AUTOSAR XML (schema 4-0-3)
standard types defined: Boolean, UInt16, UInt8
package /AUTOSAR_Platform/DataConstrs
  range DC_Boolean: raw 0..1
  range DC_UInt16: raw 0..65535
  range DC_UInt8: raw 0..255
package /PATAC/MSM/ComponentTypes
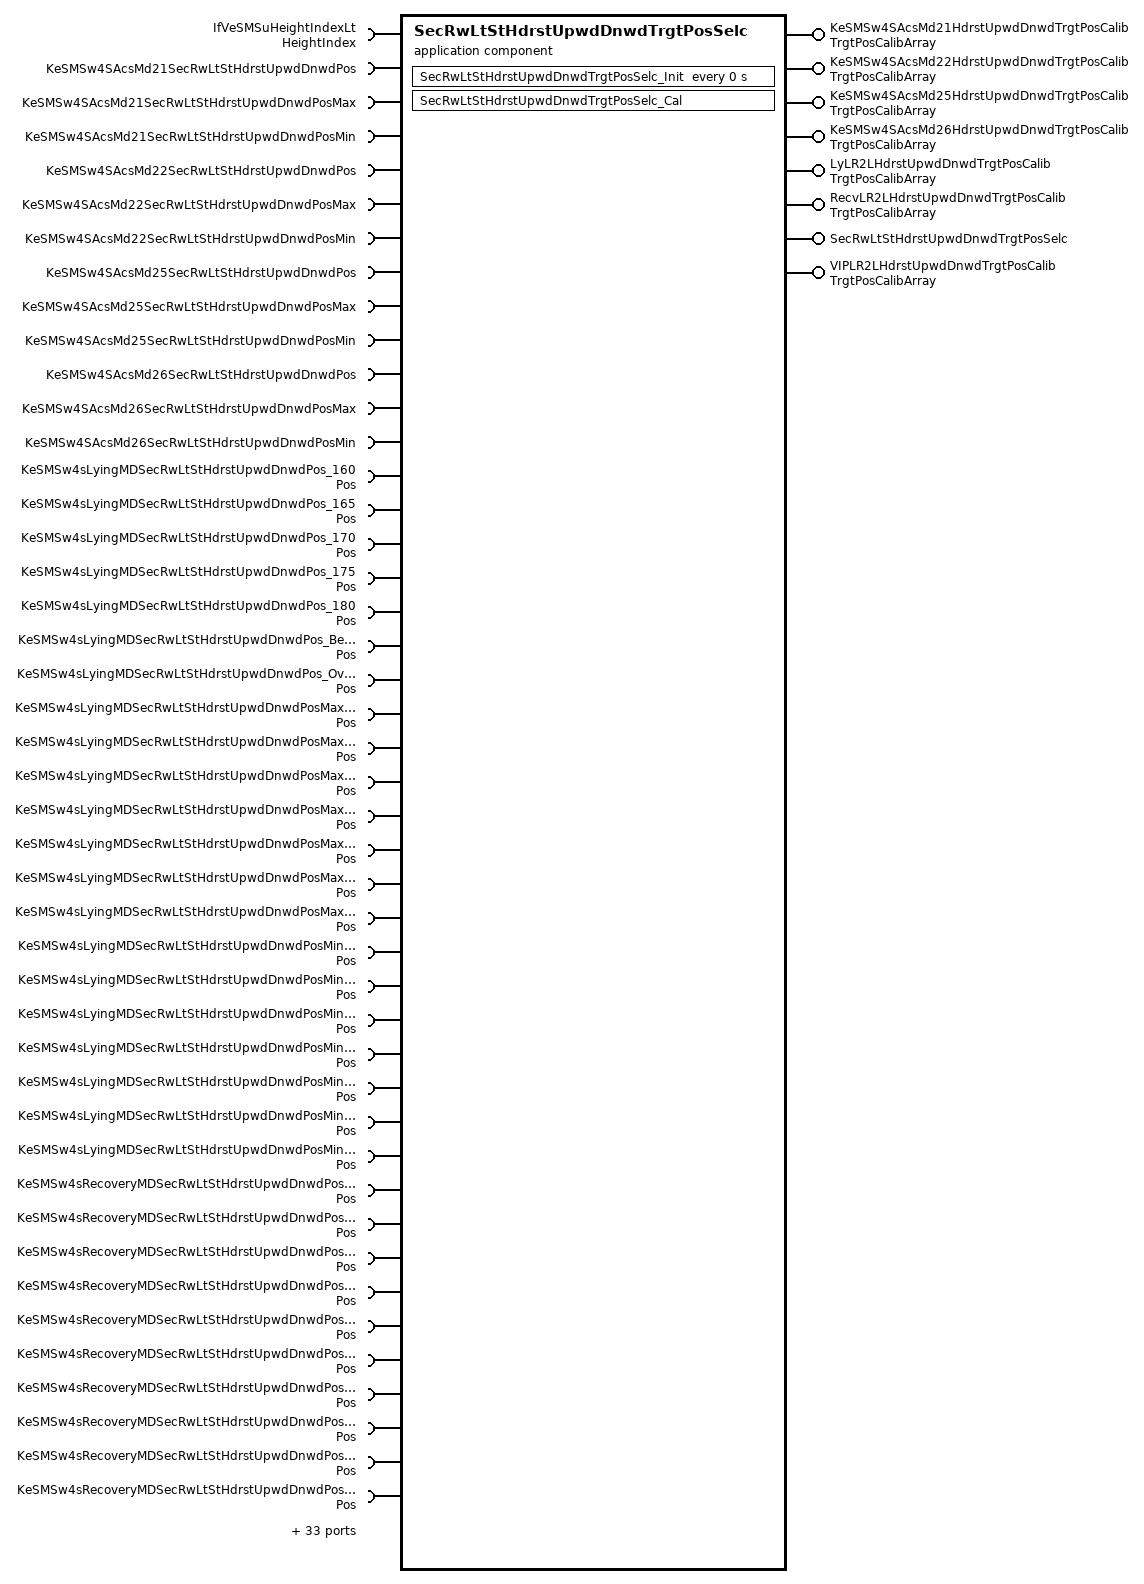
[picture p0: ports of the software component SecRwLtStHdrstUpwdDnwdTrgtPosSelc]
  application sw component type SecRwLtStHdrstUpwdDnwdTrgtPosSelc
    8 x provide port:
      KeSMSw4SAcsMd21HdrstUpwdDnwdTrgtPosCalib: nonqueued-sender-com-spec{data-element=TrgtPosArray, init-value=[4095, 4095, 4095]}, provided-interface=TrgtPosCalibArray
      KeSMSw4SAcsMd22HdrstUpwdDnwdTrgtPosCalib: nonqueued-sender-com-spec{data-element=TrgtPosArray, init-value=[4095, 4095, 4095]}, provided-interface=TrgtPosCalibArray
      KeSMSw4SAcsMd25HdrstUpwdDnwdTrgtPosCalib: nonqueued-sender-com-spec{data-element=TrgtPosArray, init-value=[4095, 4095, 4095]}, provided-interface=TrgtPosCalibArray
      KeSMSw4SAcsMd26HdrstUpwdDnwdTrgtPosCalib: nonqueued-sender-com-spec{data-element=TrgtPosArray, init-value=[4095, 4095, 4095]}, provided-interface=TrgtPosCalibArray
      LyLR2LHdrstUpwdDnwdTrgtPosCalib: nonqueued-sender-com-spec{data-element=TrgtPosArray, init-value=[4095, 4095, 4095]}, provided-interface=TrgtPosCalibArray
      RecvLR2LHdrstUpwdDnwdTrgtPosCalib: nonqueued-sender-com-spec{data-element=TrgtPosArray, init-value=[4095, 4095, 4095]}, provided-interface=TrgtPosCalibArray
      SecRwLtStHdrstUpwdDnwdTrgtPosSelc: server-com-spec{operation=Cal, queue-length=1}, provided-interface=SecRwLtStHdrstUpwdDnwdTrgtPosSelc
      VIPLR2LHdrstUpwdDnwdTrgtPosCalib: nonqueued-sender-com-spec{data-element=TrgtPosArray, init-value=[4095, 4095, 4095]}, provided-interface=TrgtPosCalibArray
    77 x require port:
      IfVeSMSuHeightIndexLt: nonqueued-receiver-com-spec{data-element=Val, filter=data-filter-type=ALWAYS, init-value=0}, required-interface=HeightIndex
      KeSMSw4SAcsMd21SecRwLtStHdrstUpwdDnwdPos: parameter-require-com-spec{init-value=0, parameter=KeSMSw4SAcsMd21SecRwLtStHdrstUpwdDnwdPos/Val}, required-interface=KeSMSw4SAcsMd21SecRwLtStHdrstUpwdDnwdPos
      KeSMSw4SAcsMd21SecRwLtStHdrstUpwdDnwdPosMax: parameter-require-com-spec{init-value=0, parameter=KeSMSw4SAcsMd21SecRwLtStHdrstUpwdDnwdPosMax/Val}, required-interface=KeSMSw4SAcsMd21SecRwLtStHdrstUpwdDnwdPosMax
      KeSMSw4SAcsMd21SecRwLtStHdrstUpwdDnwdPosMin: parameter-require-com-spec{init-value=0, parameter=KeSMSw4SAcsMd21SecRwLtStHdrstUpwdDnwdPosMin/Val}, required-interface=KeSMSw4SAcsMd21SecRwLtStHdrstUpwdDnwdPosMin
      KeSMSw4SAcsMd22SecRwLtStHdrstUpwdDnwdPos: parameter-require-com-spec{init-value=0, parameter=KeSMSw4SAcsMd22SecRwLtStHdrstUpwdDnwdPos/Val}, required-interface=KeSMSw4SAcsMd22SecRwLtStHdrstUpwdDnwdPos
      KeSMSw4SAcsMd22SecRwLtStHdrstUpwdDnwdPosMax: parameter-require-com-spec{init-value=0, parameter=KeSMSw4SAcsMd22SecRwLtStHdrstUpwdDnwdPosMax/Val}, required-interface=KeSMSw4SAcsMd22SecRwLtStHdrstUpwdDnwdPosMax
      KeSMSw4SAcsMd22SecRwLtStHdrstUpwdDnwdPosMin: parameter-require-com-spec{init-value=0, parameter=KeSMSw4SAcsMd22SecRwLtStHdrstUpwdDnwdPosMin/Val}, required-interface=KeSMSw4SAcsMd22SecRwLtStHdrstUpwdDnwdPosMin
      KeSMSw4SAcsMd25SecRwLtStHdrstUpwdDnwdPos: parameter-require-com-spec{init-value=0, parameter=KeSMSw4SAcsMd25SecRwLtStHdrstUpwdDnwdPos/Val}, required-interface=KeSMSw4SAcsMd25SecRwLtStHdrstUpwdDnwdPos
      KeSMSw4SAcsMd25SecRwLtStHdrstUpwdDnwdPosMax: parameter-require-com-spec{init-value=0, parameter=KeSMSw4SAcsMd25SecRwLtStHdrstUpwdDnwdPosMax/Val}, required-interface=KeSMSw4SAcsMd25SecRwLtStHdrstUpwdDnwdPosMax
      KeSMSw4SAcsMd25SecRwLtStHdrstUpwdDnwdPosMin: parameter-require-com-spec{init-value=0, parameter=KeSMSw4SAcsMd25SecRwLtStHdrstUpwdDnwdPosMin/Val}, required-interface=KeSMSw4SAcsMd25SecRwLtStHdrstUpwdDnwdPosMin
      KeSMSw4SAcsMd26SecRwLtStHdrstUpwdDnwdPos: parameter-require-com-spec{init-value=0, parameter=KeSMSw4SAcsMd26SecRwLtStHdrstUpwdDnwdPos/Val}, required-interface=KeSMSw4SAcsMd26SecRwLtStHdrstUpwdDnwdPos
      KeSMSw4SAcsMd26SecRwLtStHdrstUpwdDnwdPosMax: parameter-require-com-spec{init-value=0, parameter=KeSMSw4SAcsMd26SecRwLtStHdrstUpwdDnwdPosMax/Val}, required-interface=KeSMSw4SAcsMd26SecRwLtStHdrstUpwdDnwdPosMax
      KeSMSw4SAcsMd26SecRwLtStHdrstUpwdDnwdPosMin: parameter-require-com-spec{init-value=0, parameter=KeSMSw4SAcsMd26SecRwLtStHdrstUpwdDnwdPosMin/Val}, required-interface=KeSMSw4SAcsMd26SecRwLtStHdrstUpwdDnwdPosMin
      KeSMSw4sLyingMDSecRwLtStHdrstUpwdDnwdPos_160: parameter-require-com-spec{init-value=0, parameter=Pos/Val}, required-interface=Pos
      KeSMSw4sLyingMDSecRwLtStHdrstUpwdDnwdPos_165: parameter-require-com-spec{init-value=0, parameter=Pos/Val}, required-interface=Pos
      KeSMSw4sLyingMDSecRwLtStHdrstUpwdDnwdPos_170: parameter-require-com-spec{init-value=0, parameter=Pos/Val}, required-interface=Pos
      KeSMSw4sLyingMDSecRwLtStHdrstUpwdDnwdPos_175: parameter-require-com-spec{init-value=0, parameter=Pos/Val}, required-interface=Pos
      KeSMSw4sLyingMDSecRwLtStHdrstUpwdDnwdPos_180: parameter-require-com-spec{init-value=0, parameter=Pos/Val}, required-interface=Pos
      KeSMSw4sLyingMDSecRwLtStHdrstUpwdDnwdPos_Below160: parameter-require-com-spec{init-value=0, parameter=Pos/Val}, required-interface=Pos
      KeSMSw4sLyingMDSecRwLtStHdrstUpwdDnwdPos_Over180: parameter-require-com-spec{init-value=0, parameter=Pos/Val}, required-interface=Pos
      KeSMSw4sLyingMDSecRwLtStHdrstUpwdDnwdPosMax_160: parameter-require-com-spec{init-value=0, parameter=Pos/Val}, required-interface=Pos
      KeSMSw4sLyingMDSecRwLtStHdrstUpwdDnwdPosMax_165: parameter-require-com-spec{init-value=0, parameter=Pos/Val}, required-interface=Pos
      KeSMSw4sLyingMDSecRwLtStHdrstUpwdDnwdPosMax_170: parameter-require-com-spec{init-value=0, parameter=Pos/Val}, required-interface=Pos
      KeSMSw4sLyingMDSecRwLtStHdrstUpwdDnwdPosMax_175: parameter-require-com-spec{init-value=0, parameter=Pos/Val}, required-interface=Pos
      KeSMSw4sLyingMDSecRwLtStHdrstUpwdDnwdPosMax_180: parameter-require-com-spec{init-value=0, parameter=Pos/Val}, required-interface=Pos
      KeSMSw4sLyingMDSecRwLtStHdrstUpwdDnwdPosMax_Below160: parameter-require-com-spec{init-value=0, parameter=Pos/Val}, required-interface=Pos
      KeSMSw4sLyingMDSecRwLtStHdrstUpwdDnwdPosMax_Over180: parameter-require-com-spec{init-value=0, parameter=Pos/Val}, required-interface=Pos
      KeSMSw4sLyingMDSecRwLtStHdrstUpwdDnwdPosMin_160: parameter-require-com-spec{init-value=0, parameter=Pos/Val}, required-interface=Pos
      KeSMSw4sLyingMDSecRwLtStHdrstUpwdDnwdPosMin_165: parameter-require-com-spec{init-value=0, parameter=Pos/Val}, required-interface=Pos
      KeSMSw4sLyingMDSecRwLtStHdrstUpwdDnwdPosMin_170: parameter-require-com-spec{init-value=0, parameter=Pos/Val}, required-interface=Pos
      KeSMSw4sLyingMDSecRwLtStHdrstUpwdDnwdPosMin_175: parameter-require-com-spec{init-value=0, parameter=Pos/Val}, required-interface=Pos
      KeSMSw4sLyingMDSecRwLtStHdrstUpwdDnwdPosMin_180: parameter-require-com-spec{init-value=0, parameter=Pos/Val}, required-interface=Pos
      KeSMSw4sLyingMDSecRwLtStHdrstUpwdDnwdPosMin_Below160: parameter-require-com-spec{init-value=0, parameter=Pos/Val}, required-interface=Pos
      KeSMSw4sLyingMDSecRwLtStHdrstUpwdDnwdPosMin_Over180: parameter-require-com-spec{init-value=0, parameter=Pos/Val}, required-interface=Pos
      KeSMSw4sRecoveryMDSecRwLtStHdrstUpwdDnwdPos_160: parameter-require-com-spec{init-value=0, parameter=Pos/Val}, required-interface=Pos
      KeSMSw4sRecoveryMDSecRwLtStHdrstUpwdDnwdPos_165: parameter-require-com-spec{init-value=0, parameter=Pos/Val}, required-interface=Pos
      KeSMSw4sRecoveryMDSecRwLtStHdrstUpwdDnwdPos_170: parameter-require-com-spec{init-value=0, parameter=Pos/Val}, required-interface=Pos
      KeSMSw4sRecoveryMDSecRwLtStHdrstUpwdDnwdPos_175: parameter-require-com-spec{init-value=0, parameter=Pos/Val}, required-interface=Pos
      KeSMSw4sRecoveryMDSecRwLtStHdrstUpwdDnwdPos_180: parameter-require-com-spec{init-value=0, parameter=Pos/Val}, required-interface=Pos
      KeSMSw4sRecoveryMDSecRwLtStHdrstUpwdDnwdPos_Below160: parameter-require-com-spec{init-value=0, parameter=Pos/Val}, required-interface=Pos
      KeSMSw4sRecoveryMDSecRwLtStHdrstUpwdDnwdPos_Over180: parameter-require-com-spec{init-value=0, parameter=Pos/Val}, required-interface=Pos
      KeSMSw4sRecoveryMDSecRwLtStHdrstUpwdDnwdPosMax_160: parameter-require-com-spec{init-value=0, parameter=Pos/Val}, required-interface=Pos
      KeSMSw4sRecoveryMDSecRwLtStHdrstUpwdDnwdPosMax_165: parameter-require-com-spec{init-value=0, parameter=Pos/Val}, required-interface=Pos
      KeSMSw4sRecoveryMDSecRwLtStHdrstUpwdDnwdPosMax_170: parameter-require-com-spec{init-value=0, parameter=Pos/Val}, required-interface=Pos
      KeSMSw4sRecoveryMDSecRwLtStHdrstUpwdDnwdPosMax_175: parameter-require-com-spec{init-value=0, parameter=Pos/Val}, required-interface=Pos
      KeSMSw4sRecoveryMDSecRwLtStHdrstUpwdDnwdPosMax_180: parameter-require-com-spec{init-value=0, parameter=Pos/Val}, required-interface=Pos
      KeSMSw4sRecoveryMDSecRwLtStHdrstUpwdDnwdPosMax_Below160: parameter-require-com-spec{init-value=0, parameter=Pos/Val}, required-interface=Pos
      KeSMSw4sRecoveryMDSecRwLtStHdrstUpwdDnwdPosMax_Over180: parameter-require-com-spec{init-value=0, parameter=Pos/Val}, required-interface=Pos
      KeSMSw4sRecoveryMDSecRwLtStHdrstUpwdDnwdPosMin_160: parameter-require-com-spec{init-value=0, parameter=Pos/Val}, required-interface=Pos
      KeSMSw4sRecoveryMDSecRwLtStHdrstUpwdDnwdPosMin_165: parameter-require-com-spec{init-value=0, parameter=Pos/Val}, required-interface=Pos
      KeSMSw4sRecoveryMDSecRwLtStHdrstUpwdDnwdPosMin_170: parameter-require-com-spec{init-value=0, parameter=Pos/Val}, required-interface=Pos
      KeSMSw4sRecoveryMDSecRwLtStHdrstUpwdDnwdPosMin_175: parameter-require-com-spec{init-value=0, parameter=Pos/Val}, required-interface=Pos
      KeSMSw4sRecoveryMDSecRwLtStHdrstUpwdDnwdPosMin_180: parameter-require-com-spec{init-value=0, parameter=Pos/Val}, required-interface=Pos
      KeSMSw4sRecoveryMDSecRwLtStHdrstUpwdDnwdPosMin_Below160: parameter-require-com-spec{init-value=0, parameter=Pos/Val}, required-interface=Pos
      KeSMSw4sRecoveryMDSecRwLtStHdrstUpwdDnwdPosMin_Over180: parameter-require-com-spec{init-value=0, parameter=Pos/Val}, required-interface=Pos
      KeSMSw4sVIPMDSecRwLtStHdrstUpwdDnwdPos_160: parameter-require-com-spec{init-value=0, parameter=Pos/Val}, required-interface=Pos
      KeSMSw4sVIPMDSecRwLtStHdrstUpwdDnwdPos_165: parameter-require-com-spec{init-value=0, parameter=Pos/Val}, required-interface=Pos
      KeSMSw4sVIPMDSecRwLtStHdrstUpwdDnwdPos_170: parameter-require-com-spec{init-value=0, parameter=Pos/Val}, required-interface=Pos
      KeSMSw4sVIPMDSecRwLtStHdrstUpwdDnwdPos_175: parameter-require-com-spec{init-value=0, parameter=Pos/Val}, required-interface=Pos
      KeSMSw4sVIPMDSecRwLtStHdrstUpwdDnwdPos_180: parameter-require-com-spec{init-value=0, parameter=Pos/Val}, required-interface=Pos
      KeSMSw4sVIPMDSecRwLtStHdrstUpwdDnwdPos_Below160: parameter-require-com-spec{init-value=0, parameter=Pos/Val}, required-interface=Pos
      KeSMSw4sVIPMDSecRwLtStHdrstUpwdDnwdPos_Over180: parameter-require-com-spec{init-value=0, parameter=Pos/Val}, required-interface=Pos
      KeSMSw4sVIPMDSecRwLtStHdrstUpwdDnwdPosMax_160: parameter-require-com-spec{init-value=0, parameter=Pos/Val}, required-interface=Pos
      KeSMSw4sVIPMDSecRwLtStHdrstUpwdDnwdPosMax_165: parameter-require-com-spec{init-value=0, parameter=Pos/Val}, required-interface=Pos
      KeSMSw4sVIPMDSecRwLtStHdrstUpwdDnwdPosMax_170: parameter-require-com-spec{init-value=0, parameter=Pos/Val}, required-interface=Pos
      KeSMSw4sVIPMDSecRwLtStHdrstUpwdDnwdPosMax_175: parameter-require-com-spec{init-value=0, parameter=Pos/Val}, required-interface=Pos
      KeSMSw4sVIPMDSecRwLtStHdrstUpwdDnwdPosMax_180: parameter-require-com-spec{init-value=0, parameter=Pos/Val}, required-interface=Pos
      KeSMSw4sVIPMDSecRwLtStHdrstUpwdDnwdPosMax_Below160: parameter-require-com-spec{init-value=0, parameter=Pos/Val}, required-interface=Pos
      KeSMSw4sVIPMDSecRwLtStHdrstUpwdDnwdPosMax_Over180: parameter-require-com-spec{init-value=0, parameter=Pos/Val}, required-interface=Pos
      KeSMSw4sVIPMDSecRwLtStHdrstUpwdDnwdPosMin_160: parameter-require-com-spec{init-value=0, parameter=Pos/Val}, required-interface=Pos
      KeSMSw4sVIPMDSecRwLtStHdrstUpwdDnwdPosMin_165: parameter-require-com-spec{init-value=0, parameter=Pos/Val}, required-interface=Pos
      KeSMSw4sVIPMDSecRwLtStHdrstUpwdDnwdPosMin_170: parameter-require-com-spec{init-value=0, parameter=Pos/Val}, required-interface=Pos
      KeSMSw4sVIPMDSecRwLtStHdrstUpwdDnwdPosMin_175: parameter-require-com-spec{init-value=0, parameter=Pos/Val}, required-interface=Pos
      KeSMSw4sVIPMDSecRwLtStHdrstUpwdDnwdPosMin_180: parameter-require-com-spec{init-value=0, parameter=Pos/Val}, required-interface=Pos
      KeSMSw4sVIPMDSecRwLtStHdrstUpwdDnwdPosMin_Below160: parameter-require-com-spec{init-value=0, parameter=Pos/Val}, required-interface=Pos
      KeSMSw4sVIPMDSecRwLtStHdrstUpwdDnwdPosMin_Over180: parameter-require-com-spec{init-value=0, parameter=Pos/Val}, required-interface=Pos
      StNumFlg: required-interface=StNumFlg
        required-com-specs:
          data-element=Is4s, filter=data-filter-type=ALWAYS, init-value=0
          data-element=Is6s, filter=data-filter-type=ALWAYS, init-value=0
          data-element=Is6s7s, filter=data-filter-type=ALWAYS, init-value=0
          data-element=Is7s, filter=data-filter-type=ALWAYS, init-value=0
    behavior SecRwLtStHdrstUpwdDnwdTrgtPosSelc_InternalBehavior
      operation invoked event OIT_SecRwLtStHdrstUpwdDnwdTrgtPosSelc_Cal_SecRwLtStHdrstUpwdDnwdTrgtPosSelc_Cal: start-on-event=SecRwLtStHdrstUpwdDnwdTrgtPosSelc_Cal, operation=SecRwLtStHdrstUpwdDnwdTrgtPosSelc.Cal
      timing event SecRwLtStHdrstUpwdDnwdTrgtPosSelc_InitEvent: start-on-event=SecRwLtStHdrstUpwdDnwdTrgtPosSelc_Init, period=0
      runnable SecRwLtStHdrstUpwdDnwdTrgtPosSelc_Cal
        data-receive-point-by-arguments:
          5 x access:
            REC_IfVeSMSuHeightIndexLt_Val: accessed-variable=IfVeSMSuHeightIndexLt.Val
            REC_StNumFlg_Is4s: accessed-variable=StNumFlg.Is4s
            REC_StNumFlg_Is6s: accessed-variable=StNumFlg.Is6s
            REC_StNumFlg_Is6s7s: accessed-variable=StNumFlg.Is6s7s
            REC_StNumFlg_Is7s: accessed-variable=StNumFlg.Is7s
        data-send-points:
          7 x access:
            SEND_KeSMSw4SAcsMd21HdrstUpwdDnwdTrgtPosCalib_TrgtPosArray: accessed-variable=KeSMSw4SAcsMd21HdrstUpwdDnwdTrgtPosCalib.TrgtPosArray
            SEND_KeSMSw4SAcsMd22HdrstUpwdDnwdTrgtPosCalib_TrgtPosArray: accessed-variable=KeSMSw4SAcsMd22HdrstUpwdDnwdTrgtPosCalib.TrgtPosArray
            SEND_KeSMSw4SAcsMd25HdrstUpwdDnwdTrgtPosCalib_TrgtPosArray: accessed-variable=KeSMSw4SAcsMd25HdrstUpwdDnwdTrgtPosCalib.TrgtPosArray
            SEND_KeSMSw4SAcsMd26HdrstUpwdDnwdTrgtPosCalib_TrgtPosArray: accessed-variable=KeSMSw4SAcsMd26HdrstUpwdDnwdTrgtPosCalib.TrgtPosArray
            SEND_LyLR2LHdrstUpwdDnwdTrgtPosCalib_TrgtPosArray: accessed-variable=LyLR2LHdrstUpwdDnwdTrgtPosCalib.TrgtPosArray
            SEND_RecvLR2LHdrstUpwdDnwdTrgtPosCalib_TrgtPosArray: accessed-variable=RecvLR2LHdrstUpwdDnwdTrgtPosCalib.TrgtPosArray
            SEND_VIPLR2LHdrstUpwdDnwdTrgtPosCalib_TrgtPosArray: accessed-variable=VIPLR2LHdrstUpwdDnwdTrgtPosCalib.TrgtPosArray
        75 x parameter access:
          PA_KeSMSw4SAcsMd21SecRwLtStHdrstUpwdDnwdPos_Val: accessed-parameter=KeSMSw4SAcsMd21SecRwLtStHdrstUpwdDnwdPos.Val
          PA_KeSMSw4SAcsMd21SecRwLtStHdrstUpwdDnwdPosMax_Val: accessed-parameter=KeSMSw4SAcsMd21SecRwLtStHdrstUpwdDnwdPosMax.Val
          PA_KeSMSw4SAcsMd21SecRwLtStHdrstUpwdDnwdPosMin_Val: accessed-parameter=KeSMSw4SAcsMd21SecRwLtStHdrstUpwdDnwdPosMin.Val
          PA_KeSMSw4SAcsMd22SecRwLtStHdrstUpwdDnwdPos_Val: accessed-parameter=KeSMSw4SAcsMd22SecRwLtStHdrstUpwdDnwdPos.Val
          PA_KeSMSw4SAcsMd22SecRwLtStHdrstUpwdDnwdPosMax_Val: accessed-parameter=KeSMSw4SAcsMd22SecRwLtStHdrstUpwdDnwdPosMax.Val
          PA_KeSMSw4SAcsMd22SecRwLtStHdrstUpwdDnwdPosMin_Val: accessed-parameter=KeSMSw4SAcsMd22SecRwLtStHdrstUpwdDnwdPosMin.Val
          PA_KeSMSw4SAcsMd25SecRwLtStHdrstUpwdDnwdPos_Val: accessed-parameter=KeSMSw4SAcsMd25SecRwLtStHdrstUpwdDnwdPos.Val
          PA_KeSMSw4SAcsMd25SecRwLtStHdrstUpwdDnwdPosMax_Val: accessed-parameter=KeSMSw4SAcsMd25SecRwLtStHdrstUpwdDnwdPosMax.Val
          PA_KeSMSw4SAcsMd25SecRwLtStHdrstUpwdDnwdPosMin_Val: accessed-parameter=KeSMSw4SAcsMd25SecRwLtStHdrstUpwdDnwdPosMin.Val
          PA_KeSMSw4SAcsMd26SecRwLtStHdrstUpwdDnwdPos_Val: accessed-parameter=KeSMSw4SAcsMd26SecRwLtStHdrstUpwdDnwdPos.Val
          PA_KeSMSw4SAcsMd26SecRwLtStHdrstUpwdDnwdPosMax_Val: accessed-parameter=KeSMSw4SAcsMd26SecRwLtStHdrstUpwdDnwdPosMax.Val
          PA_KeSMSw4SAcsMd26SecRwLtStHdrstUpwdDnwdPosMin_Val: accessed-parameter=KeSMSw4SAcsMd26SecRwLtStHdrstUpwdDnwdPosMin.Val
          PA_KeSMSw4sLyingMDSecRwLtStHdrstUpwdDnwdPos_160_Val: accessed-parameter=KeSMSw4sLyingMDSecRwLtStHdrstUpwdDnwdPos_160.Val
          PA_KeSMSw4sLyingMDSecRwLtStHdrstUpwdDnwdPos_165_Val: accessed-parameter=KeSMSw4sLyingMDSecRwLtStHdrstUpwdDnwdPos_165.Val
          PA_KeSMSw4sLyingMDSecRwLtStHdrstUpwdDnwdPos_170_Val: accessed-parameter=KeSMSw4sLyingMDSecRwLtStHdrstUpwdDnwdPos_170.Val
          PA_KeSMSw4sLyingMDSecRwLtStHdrstUpwdDnwdPos_175_Val: accessed-parameter=KeSMSw4sLyingMDSecRwLtStHdrstUpwdDnwdPos_175.Val
          PA_KeSMSw4sLyingMDSecRwLtStHdrstUpwdDnwdPos_180_Val: accessed-parameter=KeSMSw4sLyingMDSecRwLtStHdrstUpwdDnwdPos_180.Val
          PA_KeSMSw4sLyingMDSecRwLtStHdrstUpwdDnwdPos_Below160_Val: accessed-parameter=KeSMSw4sLyingMDSecRwLtStHdrstUpwdDnwdPos_Below160.Val
          PA_KeSMSw4sLyingMDSecRwLtStHdrstUpwdDnwdPos_Over180_Val: accessed-parameter=KeSMSw4sLyingMDSecRwLtStHdrstUpwdDnwdPos_Over180.Val
          PA_KeSMSw4sLyingMDSecRwLtStHdrstUpwdDnwdPosMax_160_Val: accessed-parameter=KeSMSw4sLyingMDSecRwLtStHdrstUpwdDnwdPosMax_160.Val
          PA_KeSMSw4sLyingMDSecRwLtStHdrstUpwdDnwdPosMax_165_Val: accessed-parameter=KeSMSw4sLyingMDSecRwLtStHdrstUpwdDnwdPosMax_165.Val
          PA_KeSMSw4sLyingMDSecRwLtStHdrstUpwdDnwdPosMax_170_Val: accessed-parameter=KeSMSw4sLyingMDSecRwLtStHdrstUpwdDnwdPosMax_170.Val
          PA_KeSMSw4sLyingMDSecRwLtStHdrstUpwdDnwdPosMax_175_Val: accessed-parameter=KeSMSw4sLyingMDSecRwLtStHdrstUpwdDnwdPosMax_175.Val
          PA_KeSMSw4sLyingMDSecRwLtStHdrstUpwdDnwdPosMax_180_Val: accessed-parameter=KeSMSw4sLyingMDSecRwLtStHdrstUpwdDnwdPosMax_180.Val
          PA_KeSMSw4sLyingMDSecRwLtStHdrstUpwdDnwdPosMax_Below160_Val: accessed-parameter=KeSMSw4sLyingMDSecRwLtStHdrstUpwdDnwdPosMax_Below160.Val
          PA_KeSMSw4sLyingMDSecRwLtStHdrstUpwdDnwdPosMax_Over180_Val: accessed-parameter=KeSMSw4sLyingMDSecRwLtStHdrstUpwdDnwdPosMax_Over180.Val
          PA_KeSMSw4sLyingMDSecRwLtStHdrstUpwdDnwdPosMin_160_Val: accessed-parameter=KeSMSw4sLyingMDSecRwLtStHdrstUpwdDnwdPosMin_160.Val
          PA_KeSMSw4sLyingMDSecRwLtStHdrstUpwdDnwdPosMin_165_Val: accessed-parameter=KeSMSw4sLyingMDSecRwLtStHdrstUpwdDnwdPosMin_165.Val
          PA_KeSMSw4sLyingMDSecRwLtStHdrstUpwdDnwdPosMin_170_Val: accessed-parameter=KeSMSw4sLyingMDSecRwLtStHdrstUpwdDnwdPosMin_170.Val
          PA_KeSMSw4sLyingMDSecRwLtStHdrstUpwdDnwdPosMin_175_Val: accessed-parameter=KeSMSw4sLyingMDSecRwLtStHdrstUpwdDnwdPosMin_175.Val
          PA_KeSMSw4sLyingMDSecRwLtStHdrstUpwdDnwdPosMin_180_Val: accessed-parameter=KeSMSw4sLyingMDSecRwLtStHdrstUpwdDnwdPosMin_180.Val
          PA_KeSMSw4sLyingMDSecRwLtStHdrstUpwdDnwdPosMin_Below160_Val: accessed-parameter=KeSMSw4sLyingMDSecRwLtStHdrstUpwdDnwdPosMin_Below160.Val
          PA_KeSMSw4sLyingMDSecRwLtStHdrstUpwdDnwdPosMin_Over180_Val: accessed-parameter=KeSMSw4sLyingMDSecRwLtStHdrstUpwdDnwdPosMin_Over180.Val
          PA_KeSMSw4sRecoveryMDSecRwLtStHdrstUpwdDnwdPos_160_Val: accessed-parameter=KeSMSw4sRecoveryMDSecRwLtStHdrstUpwdDnwdPos_160.Val
          PA_KeSMSw4sRecoveryMDSecRwLtStHdrstUpwdDnwdPos_165_Val: accessed-parameter=KeSMSw4sRecoveryMDSecRwLtStHdrstUpwdDnwdPos_165.Val
          PA_KeSMSw4sRecoveryMDSecRwLtStHdrstUpwdDnwdPos_170_Val: accessed-parameter=KeSMSw4sRecoveryMDSecRwLtStHdrstUpwdDnwdPos_170.Val
          PA_KeSMSw4sRecoveryMDSecRwLtStHdrstUpwdDnwdPos_175_Val: accessed-parameter=KeSMSw4sRecoveryMDSecRwLtStHdrstUpwdDnwdPos_175.Val
          PA_KeSMSw4sRecoveryMDSecRwLtStHdrstUpwdDnwdPos_180_Val: accessed-parameter=KeSMSw4sRecoveryMDSecRwLtStHdrstUpwdDnwdPos_180.Val
          PA_KeSMSw4sRecoveryMDSecRwLtStHdrstUpwdDnwdPos_Below160_Val: accessed-parameter=KeSMSw4sRecoveryMDSecRwLtStHdrstUpwdDnwdPos_Below160.Val
          PA_KeSMSw4sRecoveryMDSecRwLtStHdrstUpwdDnwdPos_Over180_Val: accessed-parameter=KeSMSw4sRecoveryMDSecRwLtStHdrstUpwdDnwdPos_Over180.Val
          PA_KeSMSw4sRecoveryMDSecRwLtStHdrstUpwdDnwdPosMax_160_Val: accessed-parameter=KeSMSw4sRecoveryMDSecRwLtStHdrstUpwdDnwdPosMax_160.Val
          PA_KeSMSw4sRecoveryMDSecRwLtStHdrstUpwdDnwdPosMax_165_Val: accessed-parameter=KeSMSw4sRecoveryMDSecRwLtStHdrstUpwdDnwdPosMax_165.Val
          PA_KeSMSw4sRecoveryMDSecRwLtStHdrstUpwdDnwdPosMax_170_Val: accessed-parameter=KeSMSw4sRecoveryMDSecRwLtStHdrstUpwdDnwdPosMax_170.Val
          PA_KeSMSw4sRecoveryMDSecRwLtStHdrstUpwdDnwdPosMax_175_Val: accessed-parameter=KeSMSw4sRecoveryMDSecRwLtStHdrstUpwdDnwdPosMax_175.Val
          PA_KeSMSw4sRecoveryMDSecRwLtStHdrstUpwdDnwdPosMax_180_Val: accessed-parameter=KeSMSw4sRecoveryMDSecRwLtStHdrstUpwdDnwdPosMax_180.Val
          PA_KeSMSw4sRecoveryMDSecRwLtStHdrstUpwdDnwdPosMax_Below160_Val: accessed-parameter=KeSMSw4sRecoveryMDSecRwLtStHdrstUpwdDnwdPosMax_Below160.Val
          PA_KeSMSw4sRecoveryMDSecRwLtStHdrstUpwdDnwdPosMax_Over180_Val: accessed-parameter=KeSMSw4sRecoveryMDSecRwLtStHdrstUpwdDnwdPosMax_Over180.Val
          PA_KeSMSw4sRecoveryMDSecRwLtStHdrstUpwdDnwdPosMin_160_Val: accessed-parameter=KeSMSw4sRecoveryMDSecRwLtStHdrstUpwdDnwdPosMin_160.Val
          PA_KeSMSw4sRecoveryMDSecRwLtStHdrstUpwdDnwdPosMin_165_Val: accessed-parameter=KeSMSw4sRecoveryMDSecRwLtStHdrstUpwdDnwdPosMin_165.Val
          PA_KeSMSw4sRecoveryMDSecRwLtStHdrstUpwdDnwdPosMin_170_Val: accessed-parameter=KeSMSw4sRecoveryMDSecRwLtStHdrstUpwdDnwdPosMin_170.Val
          PA_KeSMSw4sRecoveryMDSecRwLtStHdrstUpwdDnwdPosMin_175_Val: accessed-parameter=KeSMSw4sRecoveryMDSecRwLtStHdrstUpwdDnwdPosMin_175.Val
          PA_KeSMSw4sRecoveryMDSecRwLtStHdrstUpwdDnwdPosMin_180_Val: accessed-parameter=KeSMSw4sRecoveryMDSecRwLtStHdrstUpwdDnwdPosMin_180.Val
          PA_KeSMSw4sRecoveryMDSecRwLtStHdrstUpwdDnwdPosMin_Below160_Val: accessed-parameter=KeSMSw4sRecoveryMDSecRwLtStHdrstUpwdDnwdPosMin_Below160.Val
          PA_KeSMSw4sRecoveryMDSecRwLtStHdrstUpwdDnwdPosMin_Over180_Val: accessed-parameter=KeSMSw4sRecoveryMDSecRwLtStHdrstUpwdDnwdPosMin_Over180.Val
          PA_KeSMSw4sVIPMDSecRwLtStHdrstUpwdDnwdPos_160_Val: accessed-parameter=KeSMSw4sVIPMDSecRwLtStHdrstUpwdDnwdPos_160.Val
          PA_KeSMSw4sVIPMDSecRwLtStHdrstUpwdDnwdPos_165_Val: accessed-parameter=KeSMSw4sVIPMDSecRwLtStHdrstUpwdDnwdPos_165.Val
          PA_KeSMSw4sVIPMDSecRwLtStHdrstUpwdDnwdPos_170_Val: accessed-parameter=KeSMSw4sVIPMDSecRwLtStHdrstUpwdDnwdPos_170.Val
          PA_KeSMSw4sVIPMDSecRwLtStHdrstUpwdDnwdPos_175_Val: accessed-parameter=KeSMSw4sVIPMDSecRwLtStHdrstUpwdDnwdPos_175.Val
          PA_KeSMSw4sVIPMDSecRwLtStHdrstUpwdDnwdPos_180_Val: accessed-parameter=KeSMSw4sVIPMDSecRwLtStHdrstUpwdDnwdPos_180.Val
          PA_KeSMSw4sVIPMDSecRwLtStHdrstUpwdDnwdPos_Below160_Val: accessed-parameter=KeSMSw4sVIPMDSecRwLtStHdrstUpwdDnwdPos_Below160.Val
          PA_KeSMSw4sVIPMDSecRwLtStHdrstUpwdDnwdPos_Over180_Val: accessed-parameter=KeSMSw4sVIPMDSecRwLtStHdrstUpwdDnwdPos_Over180.Val
          PA_KeSMSw4sVIPMDSecRwLtStHdrstUpwdDnwdPosMax_160_Val: accessed-parameter=KeSMSw4sVIPMDSecRwLtStHdrstUpwdDnwdPosMax_160.Val
          PA_KeSMSw4sVIPMDSecRwLtStHdrstUpwdDnwdPosMax_165_Val: accessed-parameter=KeSMSw4sVIPMDSecRwLtStHdrstUpwdDnwdPosMax_165.Val
          PA_KeSMSw4sVIPMDSecRwLtStHdrstUpwdDnwdPosMax_170_Val: accessed-parameter=KeSMSw4sVIPMDSecRwLtStHdrstUpwdDnwdPosMax_170.Val
          PA_KeSMSw4sVIPMDSecRwLtStHdrstUpwdDnwdPosMax_175_Val: accessed-parameter=KeSMSw4sVIPMDSecRwLtStHdrstUpwdDnwdPosMax_175.Val
          PA_KeSMSw4sVIPMDSecRwLtStHdrstUpwdDnwdPosMax_180_Val: accessed-parameter=KeSMSw4sVIPMDSecRwLtStHdrstUpwdDnwdPosMax_180.Val
          PA_KeSMSw4sVIPMDSecRwLtStHdrstUpwdDnwdPosMax_Below160_Val: accessed-parameter=KeSMSw4sVIPMDSecRwLtStHdrstUpwdDnwdPosMax_Below160.Val
          PA_KeSMSw4sVIPMDSecRwLtStHdrstUpwdDnwdPosMax_Over180_Val: accessed-parameter=KeSMSw4sVIPMDSecRwLtStHdrstUpwdDnwdPosMax_Over180.Val
          PA_KeSMSw4sVIPMDSecRwLtStHdrstUpwdDnwdPosMin_160_Val: accessed-parameter=KeSMSw4sVIPMDSecRwLtStHdrstUpwdDnwdPosMin_160.Val
          PA_KeSMSw4sVIPMDSecRwLtStHdrstUpwdDnwdPosMin_165_Val: accessed-parameter=KeSMSw4sVIPMDSecRwLtStHdrstUpwdDnwdPosMin_165.Val
          PA_KeSMSw4sVIPMDSecRwLtStHdrstUpwdDnwdPosMin_170_Val: accessed-parameter=KeSMSw4sVIPMDSecRwLtStHdrstUpwdDnwdPosMin_170.Val
          PA_KeSMSw4sVIPMDSecRwLtStHdrstUpwdDnwdPosMin_175_Val: accessed-parameter=KeSMSw4sVIPMDSecRwLtStHdrstUpwdDnwdPosMin_175.Val
          PA_KeSMSw4sVIPMDSecRwLtStHdrstUpwdDnwdPosMin_180_Val: accessed-parameter=KeSMSw4sVIPMDSecRwLtStHdrstUpwdDnwdPosMin_180.Val
          PA_KeSMSw4sVIPMDSecRwLtStHdrstUpwdDnwdPosMin_Below160_Val: accessed-parameter=KeSMSw4sVIPMDSecRwLtStHdrstUpwdDnwdPosMin_Below160.Val
          PA_KeSMSw4sVIPMDSecRwLtStHdrstUpwdDnwdPosMin_Over180_Val: accessed-parameter=KeSMSw4sVIPMDSecRwLtStHdrstUpwdDnwdPosMin_Over180.Val
      runnable SecRwLtStHdrstUpwdDnwdTrgtPosSelc_Init
        75 x parameter access:
          PA_KeSMSw4SAcsMd21SecRwLtStHdrstUpwdDnwdPos_Val: accessed-parameter=KeSMSw4SAcsMd21SecRwLtStHdrstUpwdDnwdPos.Val
          PA_KeSMSw4SAcsMd21SecRwLtStHdrstUpwdDnwdPosMax_Val: accessed-parameter=KeSMSw4SAcsMd21SecRwLtStHdrstUpwdDnwdPosMax.Val
          PA_KeSMSw4SAcsMd21SecRwLtStHdrstUpwdDnwdPosMin_Val: accessed-parameter=KeSMSw4SAcsMd21SecRwLtStHdrstUpwdDnwdPosMin.Val
          PA_KeSMSw4SAcsMd22SecRwLtStHdrstUpwdDnwdPos_Val: accessed-parameter=KeSMSw4SAcsMd22SecRwLtStHdrstUpwdDnwdPos.Val
          PA_KeSMSw4SAcsMd22SecRwLtStHdrstUpwdDnwdPosMax_Val: accessed-parameter=KeSMSw4SAcsMd22SecRwLtStHdrstUpwdDnwdPosMax.Val
          PA_KeSMSw4SAcsMd22SecRwLtStHdrstUpwdDnwdPosMin_Val: accessed-parameter=KeSMSw4SAcsMd22SecRwLtStHdrstUpwdDnwdPosMin.Val
          PA_KeSMSw4SAcsMd25SecRwLtStHdrstUpwdDnwdPos_Val: accessed-parameter=KeSMSw4SAcsMd25SecRwLtStHdrstUpwdDnwdPos.Val
          PA_KeSMSw4SAcsMd25SecRwLtStHdrstUpwdDnwdPosMax_Val: accessed-parameter=KeSMSw4SAcsMd25SecRwLtStHdrstUpwdDnwdPosMax.Val
          PA_KeSMSw4SAcsMd25SecRwLtStHdrstUpwdDnwdPosMin_Val: accessed-parameter=KeSMSw4SAcsMd25SecRwLtStHdrstUpwdDnwdPosMin.Val
          PA_KeSMSw4SAcsMd26SecRwLtStHdrstUpwdDnwdPos_Val: accessed-parameter=KeSMSw4SAcsMd26SecRwLtStHdrstUpwdDnwdPos.Val
          PA_KeSMSw4SAcsMd26SecRwLtStHdrstUpwdDnwdPosMax_Val: accessed-parameter=KeSMSw4SAcsMd26SecRwLtStHdrstUpwdDnwdPosMax.Val
          PA_KeSMSw4SAcsMd26SecRwLtStHdrstUpwdDnwdPosMin_Val: accessed-parameter=KeSMSw4SAcsMd26SecRwLtStHdrstUpwdDnwdPosMin.Val
          PA_KeSMSw4sLyingMDSecRwLtStHdrstUpwdDnwdPos_160_Val: accessed-parameter=KeSMSw4sLyingMDSecRwLtStHdrstUpwdDnwdPos_160.Val
          PA_KeSMSw4sLyingMDSecRwLtStHdrstUpwdDnwdPos_165_Val: accessed-parameter=KeSMSw4sLyingMDSecRwLtStHdrstUpwdDnwdPos_165.Val
          PA_KeSMSw4sLyingMDSecRwLtStHdrstUpwdDnwdPos_170_Val: accessed-parameter=KeSMSw4sLyingMDSecRwLtStHdrstUpwdDnwdPos_170.Val
          PA_KeSMSw4sLyingMDSecRwLtStHdrstUpwdDnwdPos_175_Val: accessed-parameter=KeSMSw4sLyingMDSecRwLtStHdrstUpwdDnwdPos_175.Val
          PA_KeSMSw4sLyingMDSecRwLtStHdrstUpwdDnwdPos_180_Val: accessed-parameter=KeSMSw4sLyingMDSecRwLtStHdrstUpwdDnwdPos_180.Val
          PA_KeSMSw4sLyingMDSecRwLtStHdrstUpwdDnwdPos_Below160_Val: accessed-parameter=KeSMSw4sLyingMDSecRwLtStHdrstUpwdDnwdPos_Below160.Val
          PA_KeSMSw4sLyingMDSecRwLtStHdrstUpwdDnwdPos_Over180_Val: accessed-parameter=KeSMSw4sLyingMDSecRwLtStHdrstUpwdDnwdPos_Over180.Val
          PA_KeSMSw4sLyingMDSecRwLtStHdrstUpwdDnwdPosMax_160_Val: accessed-parameter=KeSMSw4sLyingMDSecRwLtStHdrstUpwdDnwdPosMax_160.Val
          PA_KeSMSw4sLyingMDSecRwLtStHdrstUpwdDnwdPosMax_165_Val: accessed-parameter=KeSMSw4sLyingMDSecRwLtStHdrstUpwdDnwdPosMax_165.Val
          PA_KeSMSw4sLyingMDSecRwLtStHdrstUpwdDnwdPosMax_170_Val: accessed-parameter=KeSMSw4sLyingMDSecRwLtStHdrstUpwdDnwdPosMax_170.Val
          PA_KeSMSw4sLyingMDSecRwLtStHdrstUpwdDnwdPosMax_175_Val: accessed-parameter=KeSMSw4sLyingMDSecRwLtStHdrstUpwdDnwdPosMax_175.Val
          PA_KeSMSw4sLyingMDSecRwLtStHdrstUpwdDnwdPosMax_180_Val: accessed-parameter=KeSMSw4sLyingMDSecRwLtStHdrstUpwdDnwdPosMax_180.Val
          PA_KeSMSw4sLyingMDSecRwLtStHdrstUpwdDnwdPosMax_Below160_Val: accessed-parameter=KeSMSw4sLyingMDSecRwLtStHdrstUpwdDnwdPosMax_Below160.Val
          PA_KeSMSw4sLyingMDSecRwLtStHdrstUpwdDnwdPosMax_Over180_Val: accessed-parameter=KeSMSw4sLyingMDSecRwLtStHdrstUpwdDnwdPosMax_Over180.Val
          PA_KeSMSw4sLyingMDSecRwLtStHdrstUpwdDnwdPosMin_160_Val: accessed-parameter=KeSMSw4sLyingMDSecRwLtStHdrstUpwdDnwdPosMin_160.Val
          PA_KeSMSw4sLyingMDSecRwLtStHdrstUpwdDnwdPosMin_165_Val: accessed-parameter=KeSMSw4sLyingMDSecRwLtStHdrstUpwdDnwdPosMin_165.Val
          PA_KeSMSw4sLyingMDSecRwLtStHdrstUpwdDnwdPosMin_170_Val: accessed-parameter=KeSMSw4sLyingMDSecRwLtStHdrstUpwdDnwdPosMin_170.Val
          PA_KeSMSw4sLyingMDSecRwLtStHdrstUpwdDnwdPosMin_175_Val: accessed-parameter=KeSMSw4sLyingMDSecRwLtStHdrstUpwdDnwdPosMin_175.Val
          PA_KeSMSw4sLyingMDSecRwLtStHdrstUpwdDnwdPosMin_180_Val: accessed-parameter=KeSMSw4sLyingMDSecRwLtStHdrstUpwdDnwdPosMin_180.Val
          PA_KeSMSw4sLyingMDSecRwLtStHdrstUpwdDnwdPosMin_Below160_Val: accessed-parameter=KeSMSw4sLyingMDSecRwLtStHdrstUpwdDnwdPosMin_Below160.Val
          PA_KeSMSw4sLyingMDSecRwLtStHdrstUpwdDnwdPosMin_Over180_Val: accessed-parameter=KeSMSw4sLyingMDSecRwLtStHdrstUpwdDnwdPosMin_Over180.Val
          PA_KeSMSw4sRecoveryMDSecRwLtStHdrstUpwdDnwdPos_160_Val: accessed-parameter=KeSMSw4sRecoveryMDSecRwLtStHdrstUpwdDnwdPos_160.Val
          PA_KeSMSw4sRecoveryMDSecRwLtStHdrstUpwdDnwdPos_165_Val: accessed-parameter=KeSMSw4sRecoveryMDSecRwLtStHdrstUpwdDnwdPos_165.Val
          PA_KeSMSw4sRecoveryMDSecRwLtStHdrstUpwdDnwdPos_170_Val: accessed-parameter=KeSMSw4sRecoveryMDSecRwLtStHdrstUpwdDnwdPos_170.Val
          PA_KeSMSw4sRecoveryMDSecRwLtStHdrstUpwdDnwdPos_175_Val: accessed-parameter=KeSMSw4sRecoveryMDSecRwLtStHdrstUpwdDnwdPos_175.Val
          PA_KeSMSw4sRecoveryMDSecRwLtStHdrstUpwdDnwdPos_180_Val: accessed-parameter=KeSMSw4sRecoveryMDSecRwLtStHdrstUpwdDnwdPos_180.Val
          PA_KeSMSw4sRecoveryMDSecRwLtStHdrstUpwdDnwdPos_Below160_Val: accessed-parameter=KeSMSw4sRecoveryMDSecRwLtStHdrstUpwdDnwdPos_Below160.Val
          PA_KeSMSw4sRecoveryMDSecRwLtStHdrstUpwdDnwdPos_Over180_Val: accessed-parameter=KeSMSw4sRecoveryMDSecRwLtStHdrstUpwdDnwdPos_Over180.Val
          PA_KeSMSw4sRecoveryMDSecRwLtStHdrstUpwdDnwdPosMax_160_Val: accessed-parameter=KeSMSw4sRecoveryMDSecRwLtStHdrstUpwdDnwdPosMax_160.Val
          PA_KeSMSw4sRecoveryMDSecRwLtStHdrstUpwdDnwdPosMax_165_Val: accessed-parameter=KeSMSw4sRecoveryMDSecRwLtStHdrstUpwdDnwdPosMax_165.Val
          PA_KeSMSw4sRecoveryMDSecRwLtStHdrstUpwdDnwdPosMax_170_Val: accessed-parameter=KeSMSw4sRecoveryMDSecRwLtStHdrstUpwdDnwdPosMax_170.Val
          PA_KeSMSw4sRecoveryMDSecRwLtStHdrstUpwdDnwdPosMax_175_Val: accessed-parameter=KeSMSw4sRecoveryMDSecRwLtStHdrstUpwdDnwdPosMax_175.Val
          PA_KeSMSw4sRecoveryMDSecRwLtStHdrstUpwdDnwdPosMax_180_Val: accessed-parameter=KeSMSw4sRecoveryMDSecRwLtStHdrstUpwdDnwdPosMax_180.Val
          PA_KeSMSw4sRecoveryMDSecRwLtStHdrstUpwdDnwdPosMax_Below160_Val: accessed-parameter=KeSMSw4sRecoveryMDSecRwLtStHdrstUpwdDnwdPosMax_Below160.Val
          PA_KeSMSw4sRecoveryMDSecRwLtStHdrstUpwdDnwdPosMax_Over180_Val: accessed-parameter=KeSMSw4sRecoveryMDSecRwLtStHdrstUpwdDnwdPosMax_Over180.Val
          PA_KeSMSw4sRecoveryMDSecRwLtStHdrstUpwdDnwdPosMin_160_Val: accessed-parameter=KeSMSw4sRecoveryMDSecRwLtStHdrstUpwdDnwdPosMin_160.Val
          PA_KeSMSw4sRecoveryMDSecRwLtStHdrstUpwdDnwdPosMin_165_Val: accessed-parameter=KeSMSw4sRecoveryMDSecRwLtStHdrstUpwdDnwdPosMin_165.Val
          PA_KeSMSw4sRecoveryMDSecRwLtStHdrstUpwdDnwdPosMin_170_Val: accessed-parameter=KeSMSw4sRecoveryMDSecRwLtStHdrstUpwdDnwdPosMin_170.Val
          PA_KeSMSw4sRecoveryMDSecRwLtStHdrstUpwdDnwdPosMin_175_Val: accessed-parameter=KeSMSw4sRecoveryMDSecRwLtStHdrstUpwdDnwdPosMin_175.Val
          PA_KeSMSw4sRecoveryMDSecRwLtStHdrstUpwdDnwdPosMin_180_Val: accessed-parameter=KeSMSw4sRecoveryMDSecRwLtStHdrstUpwdDnwdPosMin_180.Val
          PA_KeSMSw4sRecoveryMDSecRwLtStHdrstUpwdDnwdPosMin_Below160_Val: accessed-parameter=KeSMSw4sRecoveryMDSecRwLtStHdrstUpwdDnwdPosMin_Below160.Val
          PA_KeSMSw4sRecoveryMDSecRwLtStHdrstUpwdDnwdPosMin_Over180_Val: accessed-parameter=KeSMSw4sRecoveryMDSecRwLtStHdrstUpwdDnwdPosMin_Over180.Val
          PA_KeSMSw4sVIPMDSecRwLtStHdrstUpwdDnwdPos_160_Val: accessed-parameter=KeSMSw4sVIPMDSecRwLtStHdrstUpwdDnwdPos_160.Val
          PA_KeSMSw4sVIPMDSecRwLtStHdrstUpwdDnwdPos_165_Val: accessed-parameter=KeSMSw4sVIPMDSecRwLtStHdrstUpwdDnwdPos_165.Val
          PA_KeSMSw4sVIPMDSecRwLtStHdrstUpwdDnwdPos_170_Val: accessed-parameter=KeSMSw4sVIPMDSecRwLtStHdrstUpwdDnwdPos_170.Val
          PA_KeSMSw4sVIPMDSecRwLtStHdrstUpwdDnwdPos_175_Val: accessed-parameter=KeSMSw4sVIPMDSecRwLtStHdrstUpwdDnwdPos_175.Val
          PA_KeSMSw4sVIPMDSecRwLtStHdrstUpwdDnwdPos_180_Val: accessed-parameter=KeSMSw4sVIPMDSecRwLtStHdrstUpwdDnwdPos_180.Val
          PA_KeSMSw4sVIPMDSecRwLtStHdrstUpwdDnwdPos_Below160_Val: accessed-parameter=KeSMSw4sVIPMDSecRwLtStHdrstUpwdDnwdPos_Below160.Val
          PA_KeSMSw4sVIPMDSecRwLtStHdrstUpwdDnwdPos_Over180_Val: accessed-parameter=KeSMSw4sVIPMDSecRwLtStHdrstUpwdDnwdPos_Over180.Val
          PA_KeSMSw4sVIPMDSecRwLtStHdrstUpwdDnwdPosMax_160_Val: accessed-parameter=KeSMSw4sVIPMDSecRwLtStHdrstUpwdDnwdPosMax_160.Val
          PA_KeSMSw4sVIPMDSecRwLtStHdrstUpwdDnwdPosMax_165_Val: accessed-parameter=KeSMSw4sVIPMDSecRwLtStHdrstUpwdDnwdPosMax_165.Val
          PA_KeSMSw4sVIPMDSecRwLtStHdrstUpwdDnwdPosMax_170_Val: accessed-parameter=KeSMSw4sVIPMDSecRwLtStHdrstUpwdDnwdPosMax_170.Val
          PA_KeSMSw4sVIPMDSecRwLtStHdrstUpwdDnwdPosMax_175_Val: accessed-parameter=KeSMSw4sVIPMDSecRwLtStHdrstUpwdDnwdPosMax_175.Val
          PA_KeSMSw4sVIPMDSecRwLtStHdrstUpwdDnwdPosMax_180_Val: accessed-parameter=KeSMSw4sVIPMDSecRwLtStHdrstUpwdDnwdPosMax_180.Val
          PA_KeSMSw4sVIPMDSecRwLtStHdrstUpwdDnwdPosMax_Below160_Val: accessed-parameter=KeSMSw4sVIPMDSecRwLtStHdrstUpwdDnwdPosMax_Below160.Val
          PA_KeSMSw4sVIPMDSecRwLtStHdrstUpwdDnwdPosMax_Over180_Val: accessed-parameter=KeSMSw4sVIPMDSecRwLtStHdrstUpwdDnwdPosMax_Over180.Val
          PA_KeSMSw4sVIPMDSecRwLtStHdrstUpwdDnwdPosMin_160_Val: accessed-parameter=KeSMSw4sVIPMDSecRwLtStHdrstUpwdDnwdPosMin_160.Val
          PA_KeSMSw4sVIPMDSecRwLtStHdrstUpwdDnwdPosMin_165_Val: accessed-parameter=KeSMSw4sVIPMDSecRwLtStHdrstUpwdDnwdPosMin_165.Val
          PA_KeSMSw4sVIPMDSecRwLtStHdrstUpwdDnwdPosMin_170_Val: accessed-parameter=KeSMSw4sVIPMDSecRwLtStHdrstUpwdDnwdPosMin_170.Val
          PA_KeSMSw4sVIPMDSecRwLtStHdrstUpwdDnwdPosMin_175_Val: accessed-parameter=KeSMSw4sVIPMDSecRwLtStHdrstUpwdDnwdPosMin_175.Val
          PA_KeSMSw4sVIPMDSecRwLtStHdrstUpwdDnwdPosMin_180_Val: accessed-parameter=KeSMSw4sVIPMDSecRwLtStHdrstUpwdDnwdPosMin_180.Val
          PA_KeSMSw4sVIPMDSecRwLtStHdrstUpwdDnwdPosMin_Below160_Val: accessed-parameter=KeSMSw4sVIPMDSecRwLtStHdrstUpwdDnwdPosMin_Below160.Val
          PA_KeSMSw4sVIPMDSecRwLtStHdrstUpwdDnwdPosMin_Over180_Val: accessed-parameter=KeSMSw4sVIPMDSecRwLtStHdrstUpwdDnwdPosMin_Over180.Val
  swc implementation SecRwLtStHdrstUpwdDnwdTrgtPosSelc_Implementation: behavior=SecRwLtStHdrstUpwdDnwdTrgtPosSelc_InternalBehavior
    code-descriptors:
      code Default: artifact-descriptors=autosar-engineering-object={short-label=Default, category=SWSRC}
package /PATAC/MSM/ModeAdjust/CalPortInterface
  13 x parameter interface:
    KeSMSw4SAcsMd21SecRwLtStHdrstUpwdDnwdPos
      parameter data prototype Val: sw-calibration-access=READ-WRITE, type=UInt16
    KeSMSw4SAcsMd21SecRwLtStHdrstUpwdDnwdPosMax
      parameter data prototype Val: sw-calibration-access=READ-WRITE, type=UInt16
    KeSMSw4SAcsMd21SecRwLtStHdrstUpwdDnwdPosMin
      parameter data prototype Val: sw-calibration-access=READ-WRITE, type=UInt16
    KeSMSw4SAcsMd22SecRwLtStHdrstUpwdDnwdPos
      parameter data prototype Val: sw-calibration-access=READ-WRITE, type=UInt16
    KeSMSw4SAcsMd22SecRwLtStHdrstUpwdDnwdPosMax
      parameter data prototype Val: sw-calibration-access=READ-WRITE, type=UInt16
    KeSMSw4SAcsMd22SecRwLtStHdrstUpwdDnwdPosMin
      parameter data prototype Val: sw-calibration-access=READ-WRITE, type=UInt16
    KeSMSw4SAcsMd25SecRwLtStHdrstUpwdDnwdPos
      parameter data prototype Val: sw-calibration-access=READ-WRITE, type=UInt16
    KeSMSw4SAcsMd25SecRwLtStHdrstUpwdDnwdPosMax
      parameter data prototype Val: sw-calibration-access=READ-WRITE, type=UInt16
    KeSMSw4SAcsMd25SecRwLtStHdrstUpwdDnwdPosMin
      parameter data prototype Val: sw-calibration-access=READ-WRITE, type=UInt16
    KeSMSw4SAcsMd26SecRwLtStHdrstUpwdDnwdPos
      parameter data prototype Val: sw-calibration-access=READ-WRITE, type=UInt16
    KeSMSw4SAcsMd26SecRwLtStHdrstUpwdDnwdPosMax
      parameter data prototype Val: sw-calibration-access=READ-WRITE, type=UInt16
    KeSMSw4SAcsMd26SecRwLtStHdrstUpwdDnwdPosMin
      parameter data prototype Val: sw-calibration-access=READ-WRITE, type=UInt16
    Pos
      parameter data prototype Val: sw-calibration-access=READ-WRITE, type=UInt16
package /PATAC/MSM/ModeAdjust/DataType
  impl type TrgtPosCalibArray: category=ARRAY, sw-calibration-access=READ-ONLY, type-emitter=RTE  # 0:pos 1:max 2:min
    element Element: array-size=3, array-size-semantics=FIXED-SIZE, implementation-data-type=UInt16, invalid-value=0
package /PATAC/MSM/ModeAdjust/PortInterface
  client server interface SecRwLtStHdrstUpwdDnwdTrgtPosSelc
    operation Cal
  sender receiver interface HeightIndex: invalidation-policy{data-element=Val, handle-invalid=DONT-INVALIDATE}
    data Val: type=UInt8  # 0：under 160 1：160 2：165 3：170 4：175 5：180 6：over 180
  sender receiver interface StNumFlg
    4 x data, all with type=Boolean:
      Is4s
      Is6s
      Is6s7s
      Is7s
    invalidation-policys:
      data-element=Is7s, handle-invalid=DONT-INVALIDATE
      data-element=Is6s, handle-invalid=DONT-INVALIDATE
      data-element=Is4s, handle-invalid=DONT-INVALIDATE
      data-element=Is6s7s, handle-invalid=DONT-INVALIDATE
  sender receiver interface TrgtPosCalibArray: invalidation-policy{data-element=TrgtPosArray, handle-invalid=DONT-INVALIDATE}
    data TrgtPosArray: type=TrgtPosCalibArray  # 0:Pos 1:Max 2:Min
